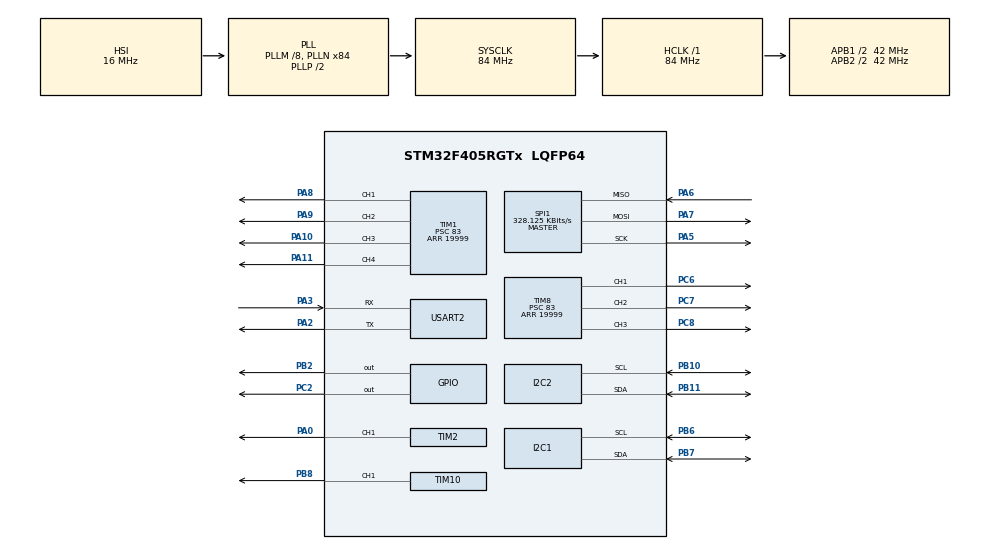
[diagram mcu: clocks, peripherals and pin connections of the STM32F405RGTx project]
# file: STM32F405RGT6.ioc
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Dma.Request0=USART2_RX
Dma.Request1=USART2_TX
Dma.USART2_RX.0.Direction=DMA_PERIPH_TO_MEMORY
Dma.USART2_RX.0.FIFOMode=DMA_FIFOMODE_DISABLE
Dma.USART2_RX.0.Instance=DMA1_Stream5
Dma.USART2_RX.0.MemDataAlignment=DMA_MDATAALIGN_BYTE
Dma.USART2_RX.0.MemInc=DMA_MINC_ENABLE
Dma.USART2_RX.0.Mode=DMA_CIRCULAR
Dma.USART2_RX.0.PeriphDataAlignment=DMA_PDATAALIGN_BYTE
Dma.USART2_RX.0.PeriphInc=DMA_PINC_DISABLE
Dma.USART2_RX.0.Priority=DMA_PRIORITY_HIGH
Dma.USART2_TX.1.Direction=DMA_MEMORY_TO_PERIPH
Dma.USART2_TX.1.FIFOMode=DMA_FIFOMODE_DISABLE
Dma.USART2_TX.1.Instance=DMA1_Stream6
Dma.USART2_TX.1.MemDataAlignment=DMA_MDATAALIGN_BYTE
Dma.USART2_TX.1.MemInc=DMA_MINC_ENABLE
Dma.USART2_TX.1.Mode=DMA_NORMAL
Dma.USART2_TX.1.PeriphDataAlignment=DMA_PDATAALIGN_BYTE
Dma.USART2_TX.1.PeriphInc=DMA_PINC_DISABLE
Dma.USART2_TX.1.Priority=DMA_PRIORITY_HIGH
FREERTOS.Tasks01=defaultTask,24,128,StartDefaultTask,Default,NULL,Dynamic,NULL,NULL
FREERTOS.configENABLE_FPU=1
FREERTOS.configTOTAL_HEAP_SIZE=32768
FREERTOS.configUSE_NEWLIB_REENTRANT=1
I2C1.NoStretchMode=I2C_NOSTRETCH_ENABLE
Mcu.Family=STM32F4
Mcu.Name=STM32F405RGTx
Mcu.Package=LQFP64
NVIC.DMA1_Stream5_IRQn=true\:5\:0\:false\:false\:true\:true\:false\:true\:true
NVIC.DMA1_Stream6_IRQn=true\:5\:0\:false\:false\:true\:true\:false\:true\:true
NVIC.FPU_IRQn=true\:5\:0\:false\:false\:true\:true\:true\:false\:true
NVIC.PriorityGroup=NVIC_PRIORITYGROUP_4
NVIC.TIM6_DAC_IRQn=true\:15\:0\:false\:false\:true\:false\:false\:true\:true
NVIC.TimeBase=TIM6_DAC_IRQn
NVIC.TimeBaseIP=TIM6
NVIC.USART2_IRQn=true\:5\:0\:false\:false\:true\:true\:true\:true\:true
PA0-WKUP.Signal=S_TIM2_CH1_ETR
PA10.Signal=S_TIM1_CH3
PA11.Signal=S_TIM1_CH4
PA2.Mode=Asynchronous
PA2.Signal=USART2_TX
PA3.Mode=Asynchronous
PA3.Signal=USART2_RX
PA5.Mode=Full_Duplex_Master
PA5.Signal=SPI1_SCK
PA6.Mode=Full_Duplex_Master
PA6.Signal=SPI1_MISO
PA7.Mode=Full_Duplex_Master
PA7.Signal=SPI1_MOSI
PA8.Signal=S_TIM1_CH1
PA9.Signal=S_TIM1_CH2
PB10.Mode=I2C
PB10.Signal=I2C2_SCL
PB11.Mode=I2C
PB11.Signal=I2C2_SDA
PB2.Signal=GPIO_Output
PB6.Mode=I2C
PB6.Signal=I2C1_SCL
PB7.Mode=I2C
PB7.Signal=I2C1_SDA
PB8.Signal=S_TIM10_CH1
PC2.Signal=GPIO_Output
PC6.Signal=S_TIM8_CH1
PC7.Signal=S_TIM8_CH2
PC8.Signal=S_TIM8_CH3
ProjectManager.HeapSize=0x200
ProjectManager.StackSize=0x400
ProjectManager.TargetToolchain=STM32CubeIDE
RCC.48MHZClocksFreq_Value=42000000
RCC.AHBFreq_Value=84000000
RCC.APB1CLKDivider=RCC_HCLK_DIV2
RCC.APB1Freq_Value=42000000
RCC.APB1TimFreq_Value=84000000
RCC.APB2CLKDivider=RCC_HCLK_DIV2
RCC.APB2Freq_Value=42000000
RCC.APB2TimFreq_Value=84000000
RCC.CortexFreq_Value=84000000
RCC.HCLKFreq_Value=84000000
RCC.HSE_VALUE=25000000
RCC.HSI_VALUE=16000000
RCC.LSE_VALUE=32768
RCC.PLLM=8
RCC.PLLN=84
RCC.SYSCLKFreq_VALUE=84000000
RCC.SYSCLKSource=RCC_SYSCLKSOURCE_PLLCLK
RCC.VCOOutputFreq_Value=168000000
SH.S_TIM10_CH1.0=TIM10_CH1,PWM Generation1 CH1
SH.S_TIM1_CH1.0=TIM1_CH1,PWM Generation1 CH1
SH.S_TIM1_CH2.0=TIM1_CH2,PWM Generation2 CH2
SH.S_TIM1_CH3.0=TIM1_CH3,PWM Generation3 CH3
SH.S_TIM1_CH4.0=TIM1_CH4,PWM Generation4 CH4
SH.S_TIM2_CH1_ETR.0=TIM2_CH1,PWM Generation1 CH1
SH.S_TIM8_CH1.0=TIM8_CH1,PWM Generation1 CH1
SH.S_TIM8_CH2.0=TIM8_CH2,PWM Generation2 CH2
SH.S_TIM8_CH3.0=TIM8_CH3,PWM Generation3 CH3
SPI1.BaudRatePrescaler=SPI_BAUDRATEPRESCALER_128
SPI1.CalculateBaudRate=328.125 KBits/s
SPI1.Direction=SPI_DIRECTION_2LINES
SPI1.Mode=SPI_MODE_MASTER
SPI1.VirtualType=VM_MASTER
TIM1.Channel-PWM\ Generation1\ CH1=TIM_CHANNEL_1
TIM1.Channel-PWM\ Generation2\ CH2=TIM_CHANNEL_2
TIM1.Channel-PWM\ Generation3\ CH3=TIM_CHANNEL_3
TIM1.Channel-PWM\ Generation4\ CH4=TIM_CHANNEL_4
TIM1.Period=19999
TIM1.Prescaler=83
TIM10.Channel=TIM_CHANNEL_1
TIM10.Period=999
TIM10.Prescaler=83
TIM2.Channel-PWM\ Generation1\ CH1=TIM_CHANNEL_1
TIM2.Period=2624
TIM2.Pulse-PWM\ Generation1\ CH1=1312
TIM8.Channel-PWM\ Generation1\ CH1=TIM_CHANNEL_1
TIM8.Channel-PWM\ Generation2\ CH2=TIM_CHANNEL_2
TIM8.Channel-PWM\ Generation3\ CH3=TIM_CHANNEL_3
TIM8.Period=19999
TIM8.Prescaler=83
USART2.VirtualMode=VM_ASYNC
VP_FREERTOS_VS_CMSIS_V2.Mode=CMSIS_V2
VP_SYS_VS_tim6.Mode=TIM6
VP_TIM10_VS_ClockSourceINT.Mode=Enable_Timer
VP_TIM1_VS_ClockSourceINT.Mode=Internal
VP_TIM2_VS_ClockSourceINT.Mode=Internal
VP_TIM8_VS_ClockSourceINT.Mode=Internal
board=custom

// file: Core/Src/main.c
#include "main.h"
#include "cmsis_os.h"
#include "control.h"

I2C_HandleTypeDef hi2c1;
I2C_HandleTypeDef hi2c2;
SPI_HandleTypeDef hspi1;
TIM_HandleTypeDef htim1;
TIM_HandleTypeDef htim2;
TIM_HandleTypeDef htim8;
TIM_HandleTypeDef htim10;
UART_HandleTypeDef huart2;
DMA_HandleTypeDef hdma_usart2_rx;
DMA_HandleTypeDef hdma_usart2_tx;

void SystemClock_Config(void);
static void MX_GPIO_Init(void);
static void MX_DMA_Init(void);
static void MX_TIM1_Init(void);
static void MX_TIM8_Init(void);
static void MX_USART2_UART_Init(void);
static void MX_SPI1_Init(void);
static void MX_TIM2_Init(void);
static void MX_I2C1_Init(void);
static void MX_I2C2_Init(void);
static void MX_TIM10_Init(void);
void StartDefaultTask(void *argument);

int main(void)
{
  HAL_Init();
  SystemClock_Config();
  MX_GPIO_Init();
  MX_DMA_Init();
  MX_TIM1_Init();
  MX_TIM8_Init();
  MX_USART2_UART_Init();
  MX_SPI1_Init();
  MX_TIM2_Init();
  MX_I2C1_Init();
  MX_I2C2_Init();
  MX_TIM10_Init();
  HAL_Delay(100);
  osKernelInitialize();
  Control_System_Init(&huart2, &hi2c1, &hi2c2, &hspi1, &htim2, &htim10);
  Thruster_Set_timer(0, &htim1, TIM_CHANNEL_1);
  Thruster_Set_timer(1, &htim1, TIM_CHANNEL_2);
  Thruster_Set_timer(2, &htim1, TIM_CHANNEL_3);
  Thruster_Set_timer(3, &htim8, TIM_CHANNEL_3);
  Thruster_Set_timer(4, &htim8, TIM_CHANNEL_1);
  Thruster_Set_timer(5, &htim8, TIM_CHANNEL_2);
  Thruster_Set_timer(6, &htim1, TIM_CHANNEL_4);
  osKernelStart();
  while (1){}
}

void SystemClock_Config(void)
{
  RCC_OscInitTypeDef RCC_OscInitStruct = {0};
  RCC_ClkInitTypeDef RCC_ClkInitStruct = {0};

  /** Configure the main internal regulator output voltage
  */
  __HAL_RCC_PWR_CLK_ENABLE();
  __HAL_PWR_VOLTAGESCALING_CONFIG(PWR_REGULATOR_VOLTAGE_SCALE1);

  /** Initializes the RCC Oscillators according to the specified parameters
  * in the RCC_OscInitTypeDef structure.
  */
  RCC_OscInitStruct.OscillatorType = RCC_OSCILLATORTYPE_HSI;
  RCC_OscInitStruct.HSIState = RCC_HSI_ON;
  RCC_OscInitStruct.HSICalibrationValue = RCC_HSICALIBRATION_DEFAULT;
  RCC_OscInitStruct.PLL.PLLState = RCC_PLL_ON;
  RCC_OscInitStruct.PLL.PLLSource = RCC_PLLSOURCE_HSI;
  RCC_OscInitStruct.PLL.PLLM = 8;
  RCC_OscInitStruct.PLL.PLLN = 84;
  RCC_OscInitStruct.PLL.PLLP = RCC_PLLP_DIV2;
  RCC_OscInitStruct.PLL.PLLQ = 4;
  if (HAL_RCC_OscConfig(&RCC_OscInitStruct) != HAL_OK)
  {
    Error_Handler();
  }

  /** Initializes the CPU, AHB and APB buses clocks
  */
  RCC_ClkInitStruct.ClockType = RCC_CLOCKTYPE_HCLK|RCC_CLOCKTYPE_SYSCLK
                              |RCC_CLOCKTYPE_PCLK1|RCC_CLOCKTYPE_PCLK2;
  RCC_ClkInitStruct.SYSCLKSource = RCC_SYSCLKSOURCE_PLLCLK;
  RCC_ClkInitStruct.AHBCLKDivider = RCC_SYSCLK_DIV1;
  RCC_ClkInitStruct.APB1CLKDivider = RCC_HCLK_DIV2;
  RCC_ClkInitStruct.APB2CLKDivider = RCC_HCLK_DIV2;

  if (HAL_RCC_ClockConfig(&RCC_ClkInitStruct, FLASH_LATENCY_2) != HAL_OK)
  {
    Error_Handler();
  }
}

static void MX_I2C1_Init(void)
{

  hi2c1.Instance = I2C1;
  hi2c1.Init.ClockSpeed = 100000;
  hi2c1.Init.DutyCycle = I2C_DUTYCYCLE_2;
  hi2c1.Init.OwnAddress1 = 0;
  hi2c1.Init.AddressingMode = I2C_ADDRESSINGMODE_7BIT;
  hi2c1.Init.DualAddressMode = I2C_DUALADDRESS_DISABLE;
  hi2c1.Init.OwnAddress2 = 0;
  hi2c1.Init.GeneralCallMode = I2C_GENERALCALL_DISABLE;
  hi2c1.Init.NoStretchMode = I2C_NOSTRETCH_ENABLE;
  if (HAL_I2C_Init(&hi2c1) != HAL_OK)
  {
    Error_Handler();
  }

}

static void MX_I2C2_Init(void)
{

  hi2c2.Instance = I2C2;
  hi2c2.Init.ClockSpeed = 100000;
  hi2c2.Init.DutyCycle = I2C_DUTYCYCLE_2;
  hi2c2.Init.OwnAddress1 = 0;
  hi2c2.Init.AddressingMode = I2C_ADDRESSINGMODE_7BIT;
  hi2c2.Init.DualAddressMode = I2C_DUALADDRESS_DISABLE;
  hi2c2.Init.OwnAddress2 = 0;
  hi2c2.Init.GeneralCallMode = I2C_GENERALCALL_DISABLE;
  hi2c2.Init.NoStretchMode = I2C_NOSTRETCH_DISABLE;
  if (HAL_I2C_Init(&hi2c2) != HAL_OK)
  {
    Error_Handler();
  }

}

static void MX_SPI1_Init(void)
{

  /* SPI1 parameter configuration*/
  hspi1.Instance = SPI1;
  hspi1.Init.Mode = SPI_MODE_MASTER;
  hspi1.Init.Direction = SPI_DIRECTION_2LINES;
  hspi1.Init.DataSize = SPI_DATASIZE_8BIT;
  hspi1.Init.CLKPolarity = SPI_POLARITY_LOW;
  hspi1.Init.CLKPhase = SPI_PHASE_1EDGE;
  hspi1.Init.NSS = SPI_NSS_SOFT;
  hspi1.Init.BaudRatePrescaler = SPI_BAUDRATEPRESCALER_256;
  hspi1.Init.FirstBit = SPI_FIRSTBIT_MSB;
  hspi1.Init.TIMode = SPI_TIMODE_DISABLE;
  hspi1.Init.CRCCalculation = SPI_CRCCALCULATION_DISABLE;
  hspi1.Init.CRCPolynomial = 10;
  if (HAL_SPI_Init(&hspi1) != HAL_OK)
  {
    Error_Handler();
  }

}

static void MX_TIM1_Init(void)
{

  TIM_ClockConfigTypeDef sClockSourceConfig = {0};
  TIM_MasterConfigTypeDef sMasterConfig = {0};
  TIM_OC_InitTypeDef sConfigOC = {0};
  TIM_BreakDeadTimeConfigTypeDef sBreakDeadTimeConfig = {0};

  htim1.Instance = TIM1;
  htim1.Init.Prescaler = 83;
  htim1.Init.CounterMode = TIM_COUNTERMODE_UP;
  htim1.Init.Period = 19999;
  htim1.Init.ClockDivision = TIM_CLOCKDIVISION_DIV1;
  htim1.Init.RepetitionCounter = 0;
  htim1.Init.AutoReloadPreload = TIM_AUTORELOAD_PRELOAD_DISABLE;
  if (HAL_TIM_Base_Init(&htim1) != HAL_OK)
  {
    Error_Handler();
  }
  sClockSourceConfig.ClockSource = TIM_CLOCKSOURCE_INTERNAL;
  if (HAL_TIM_ConfigClockSource(&htim1, &sClockSourceConfig) != HAL_OK)
  {
    Error_Handler();
  }
  if (HAL_TIM_PWM_Init(&htim1) != HAL_OK)
  {
    Error_Handler();
  }
  sMasterConfig.MasterOutputTrigger = TIM_TRGO_RESET;
  sMasterConfig.MasterSlaveMode = TIM_MASTERSLAVEMODE_DISABLE;
  if (HAL_TIMEx_MasterConfigSynchronization(&htim1, &sMasterConfig) != HAL_OK)
  {
    Error_Handler();
  }
  sConfigOC.OCMode = TIM_OCMODE_PWM1;
  sConfigOC.Pulse = 0;
  sConfigOC.OCPolarity = TIM_OCPOLARITY_HIGH;
  sConfigOC.OCNPolarity = TIM_OCNPOLARITY_HIGH;
  sConfigOC.OCFastMode = TIM_OCFAST_DISABLE;
  sConfigOC.OCIdleState = TIM_OCIDLESTATE_RESET;
  sConfigOC.OCNIdleState = TIM_OCNIDLESTATE_RESET;
  if (HAL_TIM_PWM_ConfigChannel(&htim1, &sConfigOC, TIM_CHANNEL_1) != HAL_OK)
  {
    Error_Handler();
  }
  if (HAL_TIM_PWM_ConfigChannel(&htim1, &sConfigOC, TIM_CHANNEL_2) != HAL_OK)
  {
    Error_Handler();
  }
  if (HAL_TIM_PWM_ConfigChannel(&htim1, &sConfigOC, TIM_CHANNEL_3) != HAL_OK)
  {
    Error_Handler();
  }
  if (HAL_TIM_PWM_ConfigChannel(&htim1, &sConfigOC, TIM_CHANNEL_4) != HAL_OK)
  {
    Error_Handler();
  }
  sBreakDeadTimeConfig.OffStateRunMode = TIM_OSSR_DISABLE;
  sBreakDeadTimeConfig.OffStateIDLEMode = TIM_OSSI_DISABLE;
  sBreakDeadTimeConfig.LockLevel = TIM_LOCKLEVEL_OFF;
  sBreakDeadTimeConfig.DeadTime = 0;
  sBreakDeadTimeConfig.BreakState = TIM_BREAK_DISABLE;
  sBreakDeadTimeConfig.BreakPolarity = TIM_BREAKPOLARITY_HIGH;
  sBreakDeadTimeConfig.AutomaticOutput = TIM_AUTOMATICOUTPUT_DISABLE;
  if (HAL_TIMEx_ConfigBreakDeadTime(&htim1, &sBreakDeadTimeConfig) != HAL_OK)
  {
    Error_Handler();
  }
  HAL_TIM_MspPostInit(&htim1);

}

static void MX_TIM2_Init(void)
{

  TIM_ClockConfigTypeDef sClockSourceConfig = {0};
  TIM_MasterConfigTypeDef sMasterConfig = {0};
  TIM_OC_InitTypeDef sConfigOC = {0};

  htim2.Instance = TIM2;
  htim2.Init.Prescaler = 0;
  htim2.Init.CounterMode = TIM_COUNTERMODE_UP;
  htim2.Init.Period = 2562;
  htim2.Init.ClockDivision = TIM_CLOCKDIVISION_DIV1;
  htim2.Init.AutoReloadPreload = TIM_AUTORELOAD_PRELOAD_DISABLE;
  if (HAL_TIM_Base_Init(&htim2) != HAL_OK)
  {
    Error_Handler();
  }
  sClockSourceConfig.ClockSource = TIM_CLOCKSOURCE_INTERNAL;
  if (HAL_TIM_ConfigClockSource(&htim2, &sClockSourceConfig) != HAL_OK)
  {
    Error_Handler();
  }
  if (HAL_TIM_PWM_Init(&htim2) != HAL_OK)
  {
    Error_Handler();
  }
  sMasterConfig.MasterOutputTrigger = TIM_TRGO_RESET;
  sMasterConfig.MasterSlaveMode = TIM_MASTERSLAVEMODE_DISABLE;
  if (HAL_TIMEx_MasterConfigSynchronization(&htim2, &sMasterConfig) != HAL_OK)
  {
    Error_Handler();
  }
  sConfigOC.OCMode = TIM_OCMODE_PWM1;
  sConfigOC.Pulse = 1281;
  sConfigOC.OCPolarity = TIM_OCPOLARITY_HIGH;
  sConfigOC.OCFastMode = TIM_OCFAST_DISABLE;
  if (HAL_TIM_PWM_ConfigChannel(&htim2, &sConfigOC, TIM_CHANNEL_1) != HAL_OK)
  {
    Error_Handler();
  }
  HAL_TIM_MspPostInit(&htim2);

}

static void MX_TIM8_Init(void)
{

  TIM_ClockConfigTypeDef sClockSourceConfig = {0};
  TIM_MasterConfigTypeDef sMasterConfig = {0};
  TIM_OC_InitTypeDef sConfigOC = {0};
  TIM_BreakDeadTimeConfigTypeDef sBreakDeadTimeConfig = {0};

  htim8.Instance = TIM8;
  htim8.Init.Prescaler = 83;
  htim8.Init.CounterMode = TIM_COUNTERMODE_UP;
  htim8.Init.Period = 19999;
  htim8.Init.ClockDivision = TIM_CLOCKDIVISION_DIV1;
  htim8.Init.RepetitionCounter = 0;
  htim8.Init.AutoReloadPreload = TIM_AUTORELOAD_PRELOAD_DISABLE;
  if (HAL_TIM_Base_Init(&htim8) != HAL_OK)
  {
    Error_Handler();
  }
  sClockSourceConfig.ClockSource = TIM_CLOCKSOURCE_INTERNAL;
  if (HAL_TIM_ConfigClockSource(&htim8, &sClockSourceConfig) != HAL_OK)
  {
    Error_Handler();
  }
  if (HAL_TIM_PWM_Init(&htim8) != HAL_OK)
  {
    Error_Handler();
  }
  sMasterConfig.MasterOutputTrigger = TIM_TRGO_RESET;
  sMasterConfig.MasterSlaveMode = TIM_MASTERSLAVEMODE_DISABLE;
  if (HAL_TIMEx_MasterConfigSynchronization(&htim8, &sMasterConfig) != HAL_OK)
  {
    Error_Handler();
  }
  sConfigOC.OCMode = TIM_OCMODE_PWM1;
  sConfigOC.Pulse = 0;
  sConfigOC.OCPolarity = TIM_OCPOLARITY_HIGH;
  sConfigOC.OCNPolarity = TIM_OCNPOLARITY_HIGH;
  sConfigOC.OCFastMode = TIM_OCFAST_DISABLE;
  sConfigOC.OCIdleState = TIM_OCIDLESTATE_RESET;
  sConfigOC.OCNIdleState = TIM_OCNIDLESTATE_RESET;
  if (HAL_TIM_PWM_ConfigChannel(&htim8, &sConfigOC, TIM_CHANNEL_1) != HAL_OK)
  {
    Error_Handler();
  }
  if (HAL_TIM_PWM_ConfigChannel(&htim8, &sConfigOC, TIM_CHANNEL_2) != HAL_OK)
  {
    Error_Handler();
  }
  if (HAL_TIM_PWM_ConfigChannel(&htim8, &sConfigOC, TIM_CHANNEL_3) != HAL_OK)
  {
    Error_Handler();
  }
  sBreakDeadTimeConfig.OffStateRunMode = TIM_OSSR_DISABLE;
  sBreakDeadTimeConfig.OffStateIDLEMode = TIM_OSSI_DISABLE;
  sBreakDeadTimeConfig.LockLevel = TIM_LOCKLEVEL_OFF;
  sBreakDeadTimeConfig.DeadTime = 0;
  sBreakDeadTimeConfig.BreakState = TIM_BREAK_DISABLE;
  sBreakDeadTimeConfig.BreakPolarity = TIM_BREAKPOLARITY_HIGH;
  sBreakDeadTimeConfig.AutomaticOutput = TIM_AUTOMATICOUTPUT_DISABLE;
  if (HAL_TIMEx_ConfigBreakDeadTime(&htim8, &sBreakDeadTimeConfig) != HAL_OK)
  {
    Error_Handler();
  }
  HAL_TIM_MspPostInit(&htim8);

}

static void MX_TIM10_Init(void)
{

  TIM_OC_InitTypeDef sConfigOC = {0};

  htim10.Instance = TIM10;
  htim10.Init.Prescaler = 83;
  htim10.Init.CounterMode = TIM_COUNTERMODE_UP;
  htim10.Init.Period = 999;
  htim10.Init.ClockDivision = TIM_CLOCKDIVISION_DIV1;
  htim10.Init.AutoReloadPreload = TIM_AUTORELOAD_PRELOAD_DISABLE;
  if (HAL_TIM_Base_Init(&htim10) != HAL_OK)
  {
    Error_Handler();
  }
  if (HAL_TIM_PWM_Init(&htim10) != HAL_OK)
  {
    Error_Handler();
  }
  sConfigOC.OCMode = TIM_OCMODE_PWM1;
  sConfigOC.Pulse = 0;
  sConfigOC.OCPolarity = TIM_OCPOLARITY_HIGH;
  sConfigOC.OCFastMode = TIM_OCFAST_DISABLE;
  if (HAL_TIM_PWM_ConfigChannel(&htim10, &sConfigOC, TIM_CHANNEL_1) != HAL_OK)
  {
    Error_Handler();
  }
  HAL_TIM_MspPostInit(&htim10);

}

static void MX_USART2_UART_Init(void)
{

  huart2.Instance = USART2;
  huart2.Init.BaudRate = 115200;
  huart2.Init.WordLength = UART_WORDLENGTH_8B;
  huart2.Init.StopBits = UART_STOPBITS_1;
  huart2.Init.Parity = UART_PARITY_NONE;
  huart2.Init.Mode = UART_MODE_TX_RX;
  huart2.Init.HwFlowCtl = UART_HWCONTROL_NONE;
  huart2.Init.OverSampling = UART_OVERSAMPLING_16;
  if (HAL_UART_Init(&huart2) != HAL_OK)
  {
    Error_Handler();
  }

}

static void MX_DMA_Init(void)
{

  /* DMA controller clock enable */
  __HAL_RCC_DMA1_CLK_ENABLE();

  /* DMA interrupt init */
  /* DMA1_Stream5_IRQn interrupt configuration */
  HAL_NVIC_SetPriority(DMA1_Stream5_IRQn, 5, 0);
  HAL_NVIC_EnableIRQ(DMA1_Stream5_IRQn);
  /* DMA1_Stream6_IRQn interrupt configuration */
  HAL_NVIC_SetPriority(DMA1_Stream6_IRQn, 5, 0);
  HAL_NVIC_EnableIRQ(DMA1_Stream6_IRQn);

}

static void MX_GPIO_Init(void)
{
  GPIO_InitTypeDef GPIO_InitStruct = {0};

  /* GPIO Ports Clock Enable */
  __HAL_RCC_GPIOC_CLK_ENABLE();
  __HAL_RCC_GPIOA_CLK_ENABLE();
  __HAL_RCC_GPIOB_CLK_ENABLE();

  /*Configure GPIO pin Output Level */
  HAL_GPIO_WritePin(GPIOC, GPIO_PIN_2, GPIO_PIN_RESET);

  /*Configure GPIO pin Output Level */
  HAL_GPIO_WritePin(GPIOB, GPIO_PIN_2, GPIO_PIN_RESET);

  /*Configure GPIO pin : PC2 */
  GPIO_InitStruct.Pin = GPIO_PIN_2;
  GPIO_InitStruct.Mode = GPIO_MODE_OUTPUT_PP;
  GPIO_InitStruct.Pull = GPIO_NOPULL;
  GPIO_InitStruct.Speed = GPIO_SPEED_FREQ_LOW;
  HAL_GPIO_Init(GPIOC, &GPIO_InitStruct);

  /*Configure GPIO pin : PB2 */
  GPIO_InitStruct.Pin = GPIO_PIN_2;
  GPIO_InitStruct.Mode = GPIO_MODE_OUTPUT_PP;
  GPIO_InitStruct.Pull = GPIO_NOPULL;
  GPIO_InitStruct.Speed = GPIO_SPEED_FREQ_LOW;
  HAL_GPIO_Init(GPIOB, &GPIO_InitStruct);

}

/* USER CODE BEGIN 4 */
void HAL_UART_TxCpltCallback(UART_HandleTypeDef *huart) {
    MavLink_TxCpltCallback(huart);
}
/*
void HAL_UART_ErrorCallback(UART_HandleTypeDef *huart)
{
    if (huart->Instance == USART2)
    {
        HAL_UART_Receive_DMA(huart, mavlink_rx_buffer, MAVLINK_DMA_BUFFER_SIZE);
    }
}
*/

/* USER CODE END 4 */

void StartDefaultTask(void *argument)
{
  for(;;)
  {
    osDelay(1);
  }
}

void HAL_TIM_PeriodElapsedCallback(TIM_HandleTypeDef *htim)
{
  if (htim->Instance == TIM6) {
    HAL_IncTick();
  }
}

void Error_Handler(void)
{
  __disable_irq();
  while (1)
  {
  }
}
